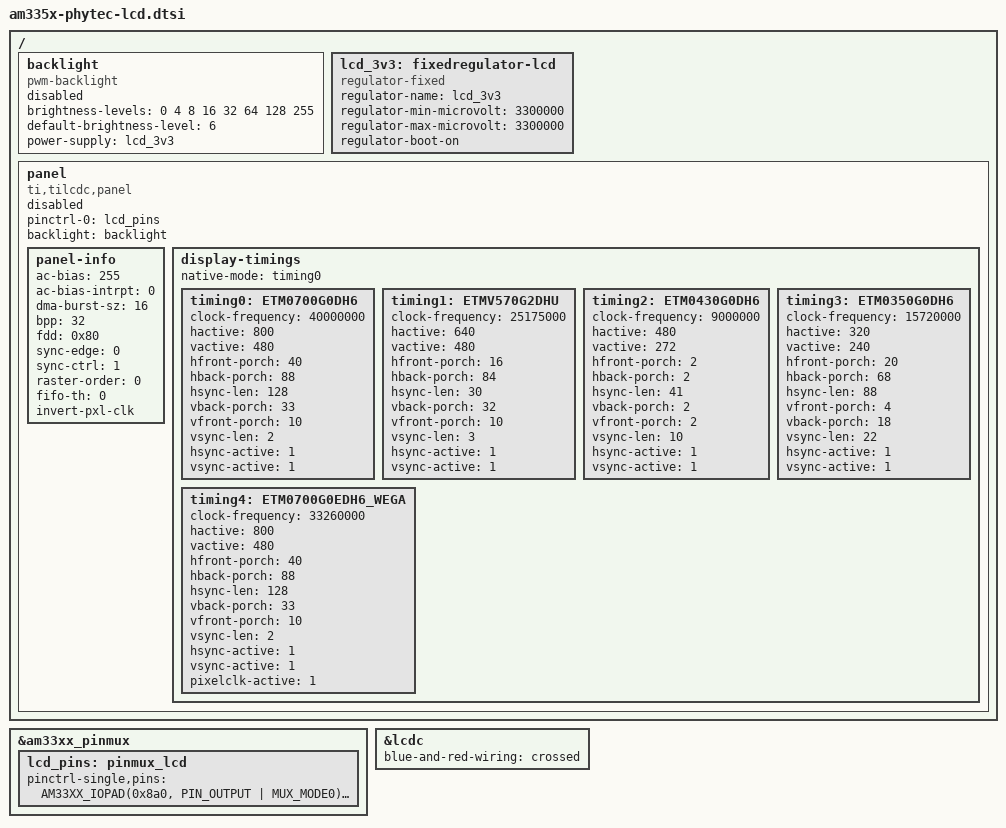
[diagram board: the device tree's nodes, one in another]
/*
 * Copyright (C) 2014 PHYTEC Messtechnik GmbH
 * Author: Wadim Egorov <w.egorov@phytec.de>
 *
 * This program is free software; you can redistribute it and/or modify
 * it under the terms of the GNU General Public License version 2 as
 * published by the Free Software Foundation.
 */

/*
 * The board specific DTS file have to:
 *  - Specify pwms and enable gpios for backlight
 *  - Mux the display enable pins if available
 *  - Add node for touch screen if available
 */

&am33xx_pinmux {
	lcd_pins: pinmux_lcd {
		pinctrl-single,pins = <
			AM33XX_IOPAD(0x8a0, PIN_OUTPUT | MUX_MODE0)	/* lcd_data0.lcd_data0 */
			AM33XX_IOPAD(0x8a4, PIN_OUTPUT | MUX_MODE0)	/* lcd_data1.lcd_data1 */
			AM33XX_IOPAD(0x8a8, PIN_OUTPUT | MUX_MODE0)	/* lcd_data2.lcd_data2 */
			AM33XX_IOPAD(0x8ac, PIN_OUTPUT | MUX_MODE0)	/* lcd_data3.lcd_data3 */
			AM33XX_IOPAD(0x8b0, PIN_OUTPUT | MUX_MODE0)	/* lcd_data4.lcd_data4 */
			AM33XX_IOPAD(0x8b4, PIN_OUTPUT | MUX_MODE0)	/* lcd_data5.lcd_data5 */
			AM33XX_IOPAD(0x8b8, PIN_OUTPUT | MUX_MODE0)	/* lcd_data6.lcd_data6 */
			AM33XX_IOPAD(0x8bc, PIN_OUTPUT | MUX_MODE0)	/* lcd_data7.lcd_data7 */
			AM33XX_IOPAD(0x8c0, PIN_OUTPUT | MUX_MODE0)	/* lcd_data8.lcd_data8 */
			AM33XX_IOPAD(0x8c4, PIN_OUTPUT | MUX_MODE0)	/* lcd_data9.lcd_data9 */
			AM33XX_IOPAD(0x8c8, PIN_OUTPUT | MUX_MODE0)	/* lcd_data10.lcd_data10 */
			AM33XX_IOPAD(0x8cc, PIN_OUTPUT | MUX_MODE0)	/* lcd_data11.lcd_data11 */
			AM33XX_IOPAD(0x8d0, PIN_OUTPUT | MUX_MODE0)	/* lcd_data12.lcd_data12 */
			AM33XX_IOPAD(0x8d4, PIN_OUTPUT | MUX_MODE0)	/* lcd_data13.lcd_data13 */
			AM33XX_IOPAD(0x8d8, PIN_OUTPUT | MUX_MODE0)	/* lcd_data14.lcd_data14 */
			AM33XX_IOPAD(0x8dc, PIN_OUTPUT | MUX_MODE0)	/* lcd_data15.lcd_data15 */
			AM33XX_IOPAD(0x83c, PIN_OUTPUT | MUX_MODE1)	/* gpmc_ad15.lcd_data16 */
			AM33XX_IOPAD(0x838, PIN_OUTPUT | MUX_MODE1)	/* gpmc_ad14.lcd_data17 */
			AM33XX_IOPAD(0x834, PIN_OUTPUT | MUX_MODE1)	/* gpmc_ad13.lcd_data18 */
			AM33XX_IOPAD(0x830, PIN_OUTPUT | MUX_MODE1)	/* gpmc_ad12.lcd_data19 */
			AM33XX_IOPAD(0x82c, PIN_OUTPUT | MUX_MODE1)	/* gpmc_ad11.lcd_data20 */
			AM33XX_IOPAD(0x828, PIN_OUTPUT | MUX_MODE1)	/* gpmc_ad10.lcd_data21 */
			AM33XX_IOPAD(0x824, PIN_OUTPUT | MUX_MODE1)	/* gpmc_ad9.lcd_data22 */
			AM33XX_IOPAD(0x820, PIN_OUTPUT | MUX_MODE1)	/* gpmc_ad8.lcd_data23 */
			AM33XX_IOPAD(0x8e0, PIN_OUTPUT | MUX_MODE0)	/* lcd_vsync.lcd_vsync */
			AM33XX_IOPAD(0x8e4, PIN_OUTPUT | MUX_MODE0)	/* lcd_hsync.lcd_hsync */
			AM33XX_IOPAD(0x8e8, PIN_OUTPUT | MUX_MODE0)	/* lcd_pclk.lcd_pclk */
			AM33XX_IOPAD(0x8ec, PIN_OUTPUT | MUX_MODE0)	/* lcd_ac_bias_en.lcd_ac_bias_en */
		>;
	};
};

&lcdc {
	blue-and-red-wiring = "crossed";
};

/ {
	backlight: backlight {
		compatible = "pwm-backlight";
		brightness-levels = <0 4 8 16 32 64 128 255>;
		default-brightness-level = <6>;
		power-supply = <&lcd_3v3>;
		status = "disabled";
	};

	lcd_3v3: fixedregulator-lcd {
		compatible = "regulator-fixed";
		regulator-name = "lcd_3v3";
		regulator-min-microvolt = <3300000>;
		regulator-max-microvolt = <3300000>;
		regulator-boot-on;
	};

	panel: panel {
		compatible = "ti,tilcdc,panel";
		pinctrl-names = "default";
		pinctrl-0 = <&lcd_pins>;
		status = "disabled";
		backlight = <&backlight>;

		panel-info {
			ac-bias = <255>;
			ac-bias-intrpt = <0>;
			dma-burst-sz = <16>;
			bpp = <32>;
			fdd = <0x80>;
			sync-edge = <0>;
			sync-ctrl = <1>;
			raster-order = <0>;
			fifo-th = <0>;
			invert-pxl-clk;
		};

		display-timings {
			native-mode = <&timing0>;
			timing0: ETM0700G0DH6 {
				clock-frequency	= <40000000>;
				hactive = <800>;
				vactive = <480>;
				hfront-porch = <40>;
				hback-porch = <88>;
				hsync-len = <128>;
				vback-porch = <33>;
				vfront-porch = <10>;
				vsync-len = <2>;
				hsync-active = <1>;
				vsync-active = <1>;
			};
			timing1: ETMV570G2DHU {
				clock-frequency	= <25175000>;
				hactive = <640>;
				vactive = <480>;
				hfront-porch = <16>;
				hback-porch = <84>;
				hsync-len = <30>;
				vback-porch = <32>;
				vfront-porch = <10>;
				vsync-len = <3>;
				hsync-active = <1>;
				vsync-active = <1>;
			};
			timing2: ETM0430G0DH6 {
				clock-frequency	= <9000000>;
				hactive = <480>;
				vactive = <272>;
				hfront-porch = <2>;
				hback-porch = <2>;
				hsync-len = <41>;
				vback-porch = <2>;
				vfront-porch = <2>;
				vsync-len = <10>;
				hsync-active = <1>;
				vsync-active = <1>;
			};
			timing3: ETM0350G0DH6 {
				clock-frequency = <15720000>;
				hactive = <320>;
				vactive = <240>;
				hfront-porch = <20>;
				hback-porch = <68>;
				hsync-len = <88>;
				vfront-porch = <4>;
				vback-porch = <18>;
				vsync-len = <22>;
				hsync-active = <1>;
				vsync-active = <1>;
			};
			timing4: ETM0700G0EDH6_WEGA {
				clock-frequency	= <33260000>;
				hactive = <800>;
				vactive = <480>;
				hfront-porch = <40>;
				hback-porch = <88>;
				hsync-len = <128>;
				vback-porch = <33>;
				vfront-porch = <10>;
				vsync-len = <2>;
				hsync-active = <1>;
				vsync-active = <1>;
				pixelclk-active = <1>;
			};
		};
	};
};
